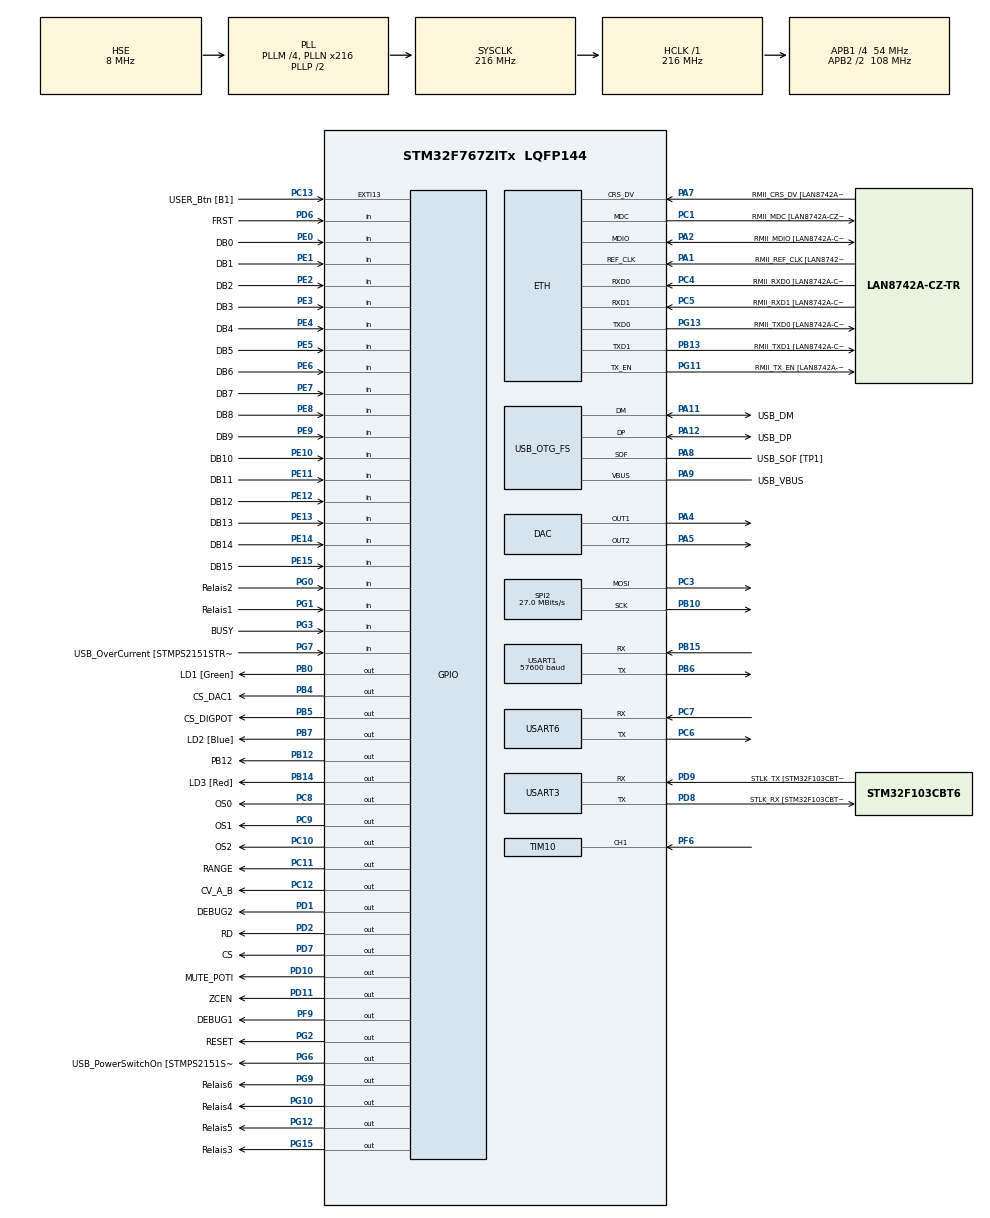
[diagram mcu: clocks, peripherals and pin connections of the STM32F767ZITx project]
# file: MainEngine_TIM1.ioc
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Dma.Request0=USART1_RX
Dma.Request1=USART6_RX
Dma.Request2=USART6_TX
Dma.USART1_RX.0.Direction=DMA_PERIPH_TO_MEMORY
Dma.USART1_RX.0.FIFOMode=DMA_FIFOMODE_DISABLE
Dma.USART1_RX.0.Instance=DMA2_Stream2
Dma.USART1_RX.0.MemDataAlignment=DMA_MDATAALIGN_BYTE
Dma.USART1_RX.0.MemInc=DMA_MINC_ENABLE
Dma.USART1_RX.0.Mode=DMA_CIRCULAR
Dma.USART1_RX.0.PeriphDataAlignment=DMA_PDATAALIGN_BYTE
Dma.USART1_RX.0.PeriphInc=DMA_PINC_DISABLE
Dma.USART1_RX.0.Priority=DMA_PRIORITY_LOW
Dma.USART6_RX.1.Direction=DMA_PERIPH_TO_MEMORY
Dma.USART6_RX.1.FIFOMode=DMA_FIFOMODE_DISABLE
Dma.USART6_RX.1.Instance=DMA2_Stream1
Dma.USART6_RX.1.MemDataAlignment=DMA_MDATAALIGN_BYTE
Dma.USART6_RX.1.MemInc=DMA_MINC_ENABLE
Dma.USART6_RX.1.Mode=DMA_CIRCULAR
Dma.USART6_RX.1.PeriphDataAlignment=DMA_PDATAALIGN_BYTE
Dma.USART6_RX.1.PeriphInc=DMA_PINC_DISABLE
Dma.USART6_RX.1.Priority=DMA_PRIORITY_LOW
Dma.USART6_TX.2.Direction=DMA_MEMORY_TO_PERIPH
Dma.USART6_TX.2.FIFOMode=DMA_FIFOMODE_DISABLE
Dma.USART6_TX.2.Instance=DMA2_Stream6
Dma.USART6_TX.2.MemDataAlignment=DMA_MDATAALIGN_BYTE
Dma.USART6_TX.2.MemInc=DMA_MINC_ENABLE
Dma.USART6_TX.2.Mode=DMA_CIRCULAR
Dma.USART6_TX.2.PeriphDataAlignment=DMA_PDATAALIGN_BYTE
Dma.USART6_TX.2.PeriphInc=DMA_PINC_DISABLE
Dma.USART6_TX.2.Priority=DMA_PRIORITY_LOW
ETH.MediaInterface=ETH_MEDIA_INTERFACE_RMII
ETH.PHY_Name=LAN8742A_PHY_ADDRESS
ETH.PHY_Value=0
ETH.PhyAddress=0
FREERTOS.Tasks01=defaultTask,0,2048,StartDefaultTask,Default,NULL,Dynamic,NULL,NULL
LWIP.IP_ADDRESS=192.168.001.070
LWIP.LWIP_DHCP=0
LWIP.LWIP_DNS=0
LWIP.LWIP_HTTPD=1
LWIP.NETMASK_ADDRESS=255.255.255.000
LWIP.Version=v2.1.2_Cube
Mcu.Family=STM32F7
Mcu.Name=STM32F767ZITx
Mcu.Package=LQFP144
NVIC.DMA2_Stream1_IRQn=true\:1\:0\:true\:false\:true\:true\:false\:true
NVIC.DMA2_Stream2_IRQn=true\:1\:0\:true\:false\:true\:true\:false\:true
NVIC.DMA2_Stream6_IRQn=true\:1\:0\:true\:false\:true\:true\:false\:true
NVIC.ETH_IRQn=true\:5\:0\:true\:false\:true\:true\:false\:true
NVIC.PriorityGroup=NVIC_PRIORITYGROUP_4
NVIC.TIM1_UP_TIM10_IRQn=true\:0\:0\:false\:false\:true\:false\:true\:true
NVIC.TIM3_IRQn=true\:3\:0\:true\:false\:true\:true\:true\:true
NVIC.TIM5_IRQn=true\:1\:0\:true\:false\:true\:true\:true\:true
NVIC.TIM6_DAC_IRQn=true\:1\:0\:true\:false\:true\:true\:true\:true
NVIC.TIM7_IRQn=true\:1\:0\:true\:false\:true\:true\:true\:true
NVIC.TimeBase=TIM1_UP_TIM10_IRQn
NVIC.TimeBaseIP=TIM1
NVIC.USART1_IRQn=true\:1\:0\:true\:false\:true\:true\:true\:true
PA1.GPIO_Label=RMII_REF_CLK [LAN8742A-CZ-TR_REFCLK0]
PA1.Mode=RMII
PA1.Signal=ETH_REF_CLK
PA10.GPIO_Label=USB_ID
PA10.Signal=USB_OTG_FS_ID
PA11.GPIO_Label=USB_DM
PA11.Mode=Device_Only
PA11.Signal=USB_OTG_FS_DM
PA12.GPIO_Label=USB_DP
PA12.Mode=Device_Only
PA12.Signal=USB_OTG_FS_DP
PA13.GPIO_Label=TMS
PA13.Mode=Serial_Wire
PA13.Signal=SYS_JTMS-SWDIO
PA14.GPIO_Label=TCK
PA14.Mode=Serial_Wire
PA14.Signal=SYS_JTCK-SWCLK
PA2.GPIO_Label=RMII_MDIO [LAN8742A-CZ-TR_MDIO]
PA2.Mode=RMII
PA2.Signal=ETH_MDIO
PA4.Signal=COMP_DAC1_group
PA5.Signal=COMP_DAC2_group
PA7.GPIO_Label=RMII_CRS_DV [LAN8742A-CZ-TR_CRS_DV]
PA7.Mode=RMII
PA7.Signal=ETH_CRS_DV
PA8.GPIO_Label=USB_SOF [TP1]
PA8.Mode=Activate_SOF_FS
PA8.Signal=USB_OTG_FS_SOF
PA9.GPIO_Label=USB_VBUS
PA9.Mode=Activate_VBUS
PA9.Signal=USB_OTG_FS_VBUS
PB0.GPIO_Label=LD1 [Green]
PB0.Signal=GPIO_Output
PB10.Mode=TX_Only_Simplex_Unidirect_Master
PB10.Signal=SPI2_SCK
PB12.GPIO_Label=PB12
PB12.Signal=GPIO_Output
PB13.GPIO_Label=RMII_TXD1 [LAN8742A-CZ-TR_TXD1]
PB13.Mode=RMII
PB13.Signal=ETH_TXD1
PB14.GPIO_Label=LD3 [Red]
PB14.Signal=GPIO_Output
PB15.Mode=Asynchronous
PB15.Signal=USART1_RX
PB3.GPIO_Label=SWO
PB3.Signal=SYS_JTDO-SWO
PB4.GPIO_Label=CS_DAC1
PB4.Signal=GPIO_Output
PB5.GPIO_Label=CS_DIGPOT
PB5.Signal=GPIO_Output
PB6.Mode=Asynchronous
PB6.Signal=USART1_TX
PB7.GPIO_Label=LD2 [Blue]
PB7.Signal=GPIO_Output
PC1.GPIO_Label=RMII_MDC [LAN8742A-CZ-TR_MDC]
PC1.Mode=RMII
PC1.Signal=ETH_MDC
PC10.GPIO_Label=OS2
PC10.Signal=GPIO_Output
PC11.GPIO_Label=RANGE
PC11.Signal=GPIO_Output
PC12.GPIO_Label=CV_A_B
PC12.Signal=GPIO_Output
PC13.GPIO_Label=USER_Btn [B1]
PC13.Signal=GPXTI13
PC14/OSC32_IN.Mode=LSE-External-Oscillator
PC14/OSC32_IN.Signal=RCC_OSC32_IN
PC15/OSC32_OUT.Mode=LSE-External-Oscillator
PC15/OSC32_OUT.Signal=RCC_OSC32_OUT
PC3.Mode=TX_Only_Simplex_Unidirect_Master
PC3.Signal=SPI2_MOSI
PC4.GPIO_Label=RMII_RXD0 [LAN8742A-CZ-TR_RXD0]
PC4.Mode=RMII
PC4.Signal=ETH_RXD0
PC5.GPIO_Label=RMII_RXD1 [LAN8742A-CZ-TR_RXD1]
PC5.Mode=RMII
PC5.Signal=ETH_RXD1
PC6.Mode=Asynchronous
PC6.Signal=USART6_TX
PC7.Mode=Asynchronous
PC7.Signal=USART6_RX
PC8.GPIO_Label=OS0
PC8.Signal=GPIO_Output
PC9.GPIO_Label=OS1
PC9.Signal=GPIO_Output
PD1.GPIO_Label=DEBUG2
PD1.Signal=GPIO_Output
PD10.GPIO_Label=MUTE_POTI
PD10.Signal=GPIO_Output
PD11.GPIO_Label=ZCEN
PD11.Signal=GPIO_Output
PD2.GPIO_Label=RD
PD2.Signal=GPIO_Output
PD6.GPIO_Label=FRST
PD6.Signal=GPIO_Input
PD7.GPIO_Label=CS
PD7.Signal=GPIO_Output
PD8.GPIO_Label=STLK_RX [STM32F103CBT6_PA3]
PD8.Mode=Asynchronous
PD8.Signal=USART3_TX
PD9.GPIO_Label=STLK_TX [STM32F103CBT6_PA2]
PD9.Mode=Asynchronous
PD9.Signal=USART3_RX
PE0.GPIO_Label=DB0
PE0.Signal=GPIO_Input
PE1.GPIO_Label=DB1
PE1.Signal=GPIO_Input
PE10.GPIO_Label=DB10
PE10.Signal=GPIO_Input
PE11.GPIO_Label=DB11
PE11.Signal=GPIO_Input
PE12.GPIO_Label=DB12
PE12.Signal=GPIO_Input
PE13.GPIO_Label=DB13
PE13.Signal=GPIO_Input
PE14.GPIO_Label=DB14
PE14.Signal=GPIO_Input
PE15.GPIO_Label=DB15
PE15.Signal=GPIO_Input
PE2.GPIO_Label=DB2
PE2.Signal=GPIO_Input
PE3.GPIO_Label=DB3
PE3.Signal=GPIO_Input
PE4.GPIO_Label=DB4
PE4.Signal=GPIO_Input
PE5.GPIO_Label=DB5
PE5.Signal=GPIO_Input
PE6.GPIO_Label=DB6
PE6.Signal=GPIO_Input
PE7.GPIO_Label=DB7
PE7.Signal=GPIO_Input
PE8.GPIO_Label=DB8
PE8.Signal=GPIO_Input
PE9.GPIO_Label=DB9
PE9.Signal=GPIO_Input
PF6.Signal=S_TIM10_CH1
PF9.GPIO_Label=DEBUG1
PF9.Signal=GPIO_Output
PG0.GPIO_Label=Relais2
PG0.Signal=GPIO_Input
PG1.GPIO_Label=Relais1
PG1.Signal=GPIO_Input
PG10.GPIO_Label=Relais4
PG10.Signal=GPIO_Output
PG11.GPIO_Label=RMII_TX_EN [LAN8742A-CZ-TR_TXEN]
PG11.Mode=RMII
PG11.Signal=ETH_TX_EN
PG12.GPIO_Label=Relais5
PG12.Signal=GPIO_Output
PG13.GPIO_Label=RMII_TXD0 [LAN8742A-CZ-TR_TXD0]
PG13.Mode=RMII
PG13.Signal=ETH_TXD0
PG15.GPIO_Label=Relais3
PG15.Signal=GPIO_Output
PG2.GPIO_Label=RESET
PG2.Signal=GPIO_Output
PG3.GPIO_Label=BUSY
PG3.Signal=GPIO_Input
PG6.GPIO_Label=USB_PowerSwitchOn [STMPS2151STR_EN]
PG6.Signal=GPIO_Output
PG7.GPIO_Label=USB_OverCurrent [STMPS2151STR_FAULT]
PG7.Signal=GPIO_Input
PG9.GPIO_Label=Relais6
PG9.Signal=GPIO_Output
PH0/OSC_IN.GPIO_Label=MCO [STM32F103CBT6_PA8]
PH0/OSC_IN.Mode=HSE-External-Clock-Source
PH0/OSC_IN.Signal=RCC_OSC_IN
PH1/OSC_OUT.Mode=HSE-External-Clock-Source
PH1/OSC_OUT.Signal=RCC_OSC_OUT
ProjectManager.HeapSize=0x200
ProjectManager.StackSize=0x400
ProjectManager.TargetToolchain=STM32CubeIDE
RCC.48MHZClocksFreq_Value=24000000
RCC.AHBFreq_Value=216000000
RCC.APB1CLKDivider=RCC_HCLK_DIV4
RCC.APB1Freq_Value=54000000
RCC.APB1TimFreq_Value=108000000
RCC.APB2CLKDivider=RCC_HCLK_DIV2
RCC.APB2Freq_Value=108000000
RCC.APB2TimFreq_Value=216000000
RCC.CortexFreq_Value=216000000
RCC.HCLKFreq_Value=216000000
RCC.HSE_VALUE=8000000
RCC.HSI_VALUE=16000000
RCC.PLLM=4
RCC.PLLMUL=RCC_PLL_MUL9
RCC.PLLN=216
RCC.PLLQ=9
RCC.PRESCALERUSB=RCC_USBCLKSOURCE_PLL_DIV1_5
RCC.SYSCLKFreq_VALUE=216000000
RCC.SYSCLKSource=RCC_SYSCLKSOURCE_PLLCLK
RCC.SYSCLKSourceVirtual=RCC_SYSCLKSOURCE_PLLCLK
RCC.USBFreq_Value=48000000
RCC.VCOOutputFreq_Value=432000000
SH.COMP_DAC1_group.0=DAC_OUT1,DAC_OUT1
SH.COMP_DAC2_group.0=DAC_OUT2,DAC_OUT2
SH.S_TIM10_CH1.0=TIM10_CH1,Input_Capture1_from_TI1
SPI2.CalculateBaudRate=27.0 MBits/s
SPI2.Direction=SPI_DIRECTION_2LINES
SPI2.Mode=SPI_MODE_MASTER
SPI2.VirtualType=VM_MASTER
TIM10.Channel=TIM_CHANNEL_1
TIM10.ICPolarity_CH1=TIM_INPUTCHANNELPOLARITY_FALLING
TIM10.Period=0
TIM10.Prescaler=107
TIM3.Period=1000
TIM3.Prescaler=216
TIM5.Period=1000
TIM5.Prescaler=216
TIM5.TIM_MasterOutputTrigger=TIM_TRGO_UPDATE
TIM6.Prescaler=107
TIM7.Prescaler=107
USART1.BaudRate=57600
USART1.VirtualMode-Asynchronous=VM_ASYNC
USART3.VirtualMode-Asynchronous=VM_ASYNC
USART6.VirtualMode-Asynchronous=VM_ASYNC
USB_OTG_FS.VirtualMode=Device_Only
VP_FREERTOS_VS_CMSIS_V1.Mode=CMSIS_V1
VP_LWIP_VS_Enabled.Mode=Enabled
VP_SYS_VS_tim1.Mode=TIM1
VP_TIM10_VS_ClockSourceINT.Mode=Enable_Timer
VP_TIM3_VS_ClockSourceINT.Mode=Internal
VP_TIM5_VS_ClockSourceINT.Mode=Internal
VP_TIM6_VS_ClockSourceINT.Mode=Enable_Timer
VP_TIM7_VS_ClockSourceINT.Mode=Enable_Timer
board=NUCLEO-F767ZI

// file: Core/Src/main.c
/* USER CODE BEGIN Header */
/**
  ******************************************************************************
  * @file           : main.c
  * @brief          : Main program body
  ******************************************************************************
  * @attention
  *
  * <h2><center>&copy; Copyright (c) 2020 STMicroelectronics.
  * All rights reserved.</center></h2>
  *
  * This software component is licensed by ST under BSD 3-Clause license,
  * the "License"; You may not use this file except in compliance with the
  * License. You may obtain a copy of the License at:
  *                        opensource.org/licenses/BSD-3-Clause
  *
  ******************************************************************************
  */
/* USER CODE END Header */
#include "main.h"
#include "cmsis_os.h"
#include "lwip.h"

/* USER CODE BEGIN Includes */
#include "lwip/tcp.h"
#include "header.h"
#include <string.h>
#include "UART-Bridge.h"
#include "dspTask.h"
/* USER CODE END Includes */

DAC_HandleTypeDef hdac;

SPI_HandleTypeDef hspi2;

TIM_HandleTypeDef htim3;
TIM_HandleTypeDef htim5;
TIM_HandleTypeDef htim6;
TIM_HandleTypeDef htim7;
TIM_HandleTypeDef htim10;

UART_HandleTypeDef huart1;
UART_HandleTypeDef huart3;
UART_HandleTypeDef huart6;
DMA_HandleTypeDef hdma_usart1_rx;
DMA_HandleTypeDef hdma_usart6_rx;
DMA_HandleTypeDef hdma_usart6_tx;

PCD_HandleTypeDef hpcd_USB_OTG_FS;

osThreadId defaultTaskHandle;
/* USER CODE BEGIN PV */
osThreadId dspTaskHandle;
/* USER CODE END PV */

void SystemClock_Config(void);
static void MX_GPIO_Init(void);
static void MX_DMA_Init(void);
static void MX_USART3_UART_Init(void);
static void MX_USB_OTG_FS_PCD_Init(void);
static void MX_TIM3_Init(void);
static void MX_USART1_UART_Init(void);
static void MX_SPI2_Init(void);
static void MX_USART6_UART_Init(void);
static void MX_DAC_Init(void);
static void MX_TIM5_Init(void);
static void MX_TIM6_Init(void);
static void MX_TIM7_Init(void);
static void MX_TIM10_Init(void);
void StartDefaultTask(void const * argument);

/* USER CODE BEGIN PFP */
static void VectorBase_Config(void);
/* USER CODE END PFP */

int main(void)
{
  /* USER CODE BEGIN 1 */
	VectorBase_Config();

  /* USER CODE END 1 */

  /* MCU Configuration--------------------------------------------------------*/

  /* Reset of all peripherals, Initializes the Flash interface and the Systick. */
  HAL_Init();

  /* Configure the system clock */
  SystemClock_Config();

  /* Initialize all configured peripherals */
  MX_GPIO_Init();
  MX_DMA_Init();
  MX_USART3_UART_Init();
  MX_USB_OTG_FS_PCD_Init();
  MX_TIM3_Init();
  MX_USART1_UART_Init();
  MX_SPI2_Init();
  MX_USART6_UART_Init();
  MX_DAC_Init();
  MX_TIM5_Init();
  MX_TIM6_Init();
  MX_TIM7_Init();
  MX_TIM10_Init();
  /* USER CODE BEGIN 2 */
  SharedParamsWriteByIndex(0, 0);
  /* USER CODE END 2 */
  HAL_DAC_Start(&hdac, DAC_CHANNEL_1);
  HAL_DAC_Start(&hdac, DAC_CHANNEL_2);

  /* Create the thread(s) */
  /* definition and creation of defaultTask */
  osThreadDef(defaultTask, StartDefaultTask, osPriorityNormal, 0, 2048);
  defaultTaskHandle = osThreadCreate(osThread(defaultTask), NULL);

  /* USER CODE BEGIN RTOS_THREADS */

  osThreadDef(dspTask, dspTask, osPriorityNormal , 0, 2000);
  dspTaskHandle = osThreadCreate(osThread(dspTask), NULL);

  /* add threads, ... */
  /* USER CODE END RTOS_THREADS */

  /* Start scheduler */
  osKernelStart();

  /* We should never get here as control is now taken by the scheduler */
  /* Infinite loop */
  /* USER CODE BEGIN WHILE */
  while (1)
  {

	  for(int i= 0; i <10 ; i++){
		  HAL_GPIO_TogglePin(GPIOB, LD1_Pin|LD3_Pin|LD2_Pin);
		  HAL_Delay(500);
	  }
    /* USER CODE END WHILE */

    /* USER CODE BEGIN 3 */
	  for(int i= 0; i <10 ; i++){
		  HAL_GPIO_TogglePin(GPIOB, LD1_Pin|LD3_Pin|LD2_Pin);
		  HAL_Delay(50);
	  }
      SharedParamsWriteByIndex(0, 1);
      /* connection request received so start the bootloader */
      BootActivate();
  }
  /* USER CODE END 3 */
}

void SystemClock_Config(void)
{
  RCC_OscInitTypeDef RCC_OscInitStruct = {0};
  RCC_ClkInitTypeDef RCC_ClkInitStruct = {0};
  RCC_PeriphCLKInitTypeDef PeriphClkInitStruct = {0};

  /** Configure LSE Drive Capability
  */
  HAL_PWR_EnableBkUpAccess();
  /** Configure the main internal regulator output voltage
  */
  __HAL_RCC_PWR_CLK_ENABLE();
  __HAL_PWR_VOLTAGESCALING_CONFIG(PWR_REGULATOR_VOLTAGE_SCALE1);
  /** Initializes the RCC Oscillators according to the specified parameters
  * in the RCC_OscInitTypeDef structure.
  */
  RCC_OscInitStruct.OscillatorType = RCC_OSCILLATORTYPE_HSE;
  RCC_OscInitStruct.HSEState = RCC_HSE_BYPASS;
  RCC_OscInitStruct.PLL.PLLState = RCC_PLL_ON;
  RCC_OscInitStruct.PLL.PLLSource = RCC_PLLSOURCE_HSE;
  RCC_OscInitStruct.PLL.PLLM = 4;
  RCC_OscInitStruct.PLL.PLLN = 216;
  RCC_OscInitStruct.PLL.PLLP = RCC_PLLP_DIV2;
  RCC_OscInitStruct.PLL.PLLQ = 9;
  if (HAL_RCC_OscConfig(&RCC_OscInitStruct) != HAL_OK)
  {
    Error_Handler();
  }
  /** Activate the Over-Drive mode
  */
  if (HAL_PWREx_EnableOverDrive() != HAL_OK)
  {
    Error_Handler();
  }
  /** Initializes the CPU, AHB and APB buses clocks
  */
  RCC_ClkInitStruct.ClockType = RCC_CLOCKTYPE_HCLK|RCC_CLOCKTYPE_SYSCLK
                              |RCC_CLOCKTYPE_PCLK1|RCC_CLOCKTYPE_PCLK2;
  RCC_ClkInitStruct.SYSCLKSource = RCC_SYSCLKSOURCE_PLLCLK;
  RCC_ClkInitStruct.AHBCLKDivider = RCC_SYSCLK_DIV1;
  RCC_ClkInitStruct.APB1CLKDivider = RCC_HCLK_DIV4;
  RCC_ClkInitStruct.APB2CLKDivider = RCC_HCLK_DIV2;

  if (HAL_RCC_ClockConfig(&RCC_ClkInitStruct, FLASH_LATENCY_7) != HAL_OK)
  {
    Error_Handler();
  }
  PeriphClkInitStruct.PeriphClockSelection = RCC_PERIPHCLK_USART1|RCC_PERIPHCLK_USART3
                              |RCC_PERIPHCLK_USART6|RCC_PERIPHCLK_CLK48;
  PeriphClkInitStruct.Usart1ClockSelection = RCC_USART1CLKSOURCE_PCLK2;
  PeriphClkInitStruct.Usart3ClockSelection = RCC_USART3CLKSOURCE_PCLK1;
  PeriphClkInitStruct.Usart6ClockSelection = RCC_USART6CLKSOURCE_PCLK2;
  PeriphClkInitStruct.Clk48ClockSelection = RCC_CLK48SOURCE_PLL;
  if (HAL_RCCEx_PeriphCLKConfig(&PeriphClkInitStruct) != HAL_OK)
  {
    Error_Handler();
  }
}

static void MX_DAC_Init(void)
{

  DAC_ChannelConfTypeDef sConfig = {0};

  /** DAC Initialization
  */
  hdac.Instance = DAC;
  if (HAL_DAC_Init(&hdac) != HAL_OK)
  {
    Error_Handler();
  }
  /** DAC channel OUT1 config
  */
  sConfig.DAC_Trigger = DAC_TRIGGER_NONE;
  sConfig.DAC_OutputBuffer = DAC_OUTPUTBUFFER_ENABLE;
  if (HAL_DAC_ConfigChannel(&hdac, &sConfig, DAC_CHANNEL_1) != HAL_OK)
  {
    Error_Handler();
  }
  /** DAC channel OUT2 config
  */
  if (HAL_DAC_ConfigChannel(&hdac, &sConfig, DAC_CHANNEL_2) != HAL_OK)
  {
    Error_Handler();
  }

}

static void MX_SPI2_Init(void)
{

  /* SPI2 parameter configuration*/
  hspi2.Instance = SPI2;
  hspi2.Init.Mode = SPI_MODE_MASTER;
  hspi2.Init.Direction = SPI_DIRECTION_2LINES;
  hspi2.Init.DataSize = SPI_DATASIZE_4BIT;
  hspi2.Init.CLKPolarity = SPI_POLARITY_LOW;
  hspi2.Init.CLKPhase = SPI_PHASE_1EDGE;
  hspi2.Init.NSS = SPI_NSS_SOFT;
  hspi2.Init.BaudRatePrescaler = SPI_BAUDRATEPRESCALER_2;
  hspi2.Init.FirstBit = SPI_FIRSTBIT_MSB;
  hspi2.Init.TIMode = SPI_TIMODE_DISABLE;
  hspi2.Init.CRCCalculation = SPI_CRCCALCULATION_DISABLE;
  hspi2.Init.CRCPolynomial = 7;
  hspi2.Init.CRCLength = SPI_CRC_LENGTH_DATASIZE;
  hspi2.Init.NSSPMode = SPI_NSS_PULSE_ENABLE;
  if (HAL_SPI_Init(&hspi2) != HAL_OK)
  {
    Error_Handler();
  }

}

static void MX_TIM3_Init(void)
{

  TIM_ClockConfigTypeDef sClockSourceConfig = {0};
  TIM_MasterConfigTypeDef sMasterConfig = {0};

  htim3.Instance = TIM3;
  htim3.Init.Prescaler = 216;
  htim3.Init.CounterMode = TIM_COUNTERMODE_UP;
  htim3.Init.Period = 1000;
  htim3.Init.ClockDivision = TIM_CLOCKDIVISION_DIV1;
  htim3.Init.AutoReloadPreload = TIM_AUTORELOAD_PRELOAD_DISABLE;
  if (HAL_TIM_Base_Init(&htim3) != HAL_OK)
  {
    Error_Handler();
  }
  sClockSourceConfig.ClockSource = TIM_CLOCKSOURCE_INTERNAL;
  if (HAL_TIM_ConfigClockSource(&htim3, &sClockSourceConfig) != HAL_OK)
  {
    Error_Handler();
  }
  sMasterConfig.MasterOutputTrigger = TIM_TRGO_RESET;
  sMasterConfig.MasterSlaveMode = TIM_MASTERSLAVEMODE_DISABLE;
  if (HAL_TIMEx_MasterConfigSynchronization(&htim3, &sMasterConfig) != HAL_OK)
  {
    Error_Handler();
  }

}

static void MX_TIM5_Init(void)
{

  TIM_ClockConfigTypeDef sClockSourceConfig = {0};
  TIM_MasterConfigTypeDef sMasterConfig = {0};

  htim5.Instance = TIM5;
  htim5.Init.Prescaler = 216;
  htim5.Init.CounterMode = TIM_COUNTERMODE_UP;
  htim5.Init.Period = 1000;
  htim5.Init.ClockDivision = TIM_CLOCKDIVISION_DIV1;
  htim5.Init.AutoReloadPreload = TIM_AUTORELOAD_PRELOAD_DISABLE;
  if (HAL_TIM_Base_Init(&htim5) != HAL_OK)
  {
    Error_Handler();
  }
  sClockSourceConfig.ClockSource = TIM_CLOCKSOURCE_INTERNAL;
  if (HAL_TIM_ConfigClockSource(&htim5, &sClockSourceConfig) != HAL_OK)
  {
    Error_Handler();
  }
  sMasterConfig.MasterOutputTrigger = TIM_TRGO_UPDATE;
  sMasterConfig.MasterSlaveMode = TIM_MASTERSLAVEMODE_DISABLE;
  if (HAL_TIMEx_MasterConfigSynchronization(&htim5, &sMasterConfig) != HAL_OK)
  {
    Error_Handler();
  }

}

static void MX_TIM6_Init(void)
{

  TIM_MasterConfigTypeDef sMasterConfig = {0};

  htim6.Instance = TIM6;
  htim6.Init.Prescaler = 107;
  htim6.Init.CounterMode = TIM_COUNTERMODE_UP;
  htim6.Init.Period = 65535;
  htim6.Init.AutoReloadPreload = TIM_AUTORELOAD_PRELOAD_DISABLE;
  if (HAL_TIM_Base_Init(&htim6) != HAL_OK)
  {
    Error_Handler();
  }
  sMasterConfig.MasterOutputTrigger = TIM_TRGO_RESET;
  sMasterConfig.MasterSlaveMode = TIM_MASTERSLAVEMODE_DISABLE;
  if (HAL_TIMEx_MasterConfigSynchronization(&htim6, &sMasterConfig) != HAL_OK)
  {
    Error_Handler();
  }

}

static void MX_TIM7_Init(void)
{

  TIM_MasterConfigTypeDef sMasterConfig = {0};

  htim7.Instance = TIM7;
  htim7.Init.Prescaler = 107;
  htim7.Init.CounterMode = TIM_COUNTERMODE_UP;
  htim7.Init.Period = 65535;
  htim7.Init.AutoReloadPreload = TIM_AUTORELOAD_PRELOAD_DISABLE;
  if (HAL_TIM_Base_Init(&htim7) != HAL_OK)
  {
    Error_Handler();
  }
  sMasterConfig.MasterOutputTrigger = TIM_TRGO_RESET;
  sMasterConfig.MasterSlaveMode = TIM_MASTERSLAVEMODE_DISABLE;
  if (HAL_TIMEx_MasterConfigSynchronization(&htim7, &sMasterConfig) != HAL_OK)
  {
    Error_Handler();
  }

}

static void MX_TIM10_Init(void)
{

  TIM_IC_InitTypeDef sConfigIC = {0};

  htim10.Instance = TIM10;
  htim10.Init.Prescaler = 107;
  htim10.Init.CounterMode = TIM_COUNTERMODE_UP;
  htim10.Init.Period = 0;
  htim10.Init.ClockDivision = TIM_CLOCKDIVISION_DIV1;
  htim10.Init.AutoReloadPreload = TIM_AUTORELOAD_PRELOAD_DISABLE;
  if (HAL_TIM_Base_Init(&htim10) != HAL_OK)
  {
    Error_Handler();
  }
  if (HAL_TIM_IC_Init(&htim10) != HAL_OK)
  {
    Error_Handler();
  }
  sConfigIC.ICPolarity = TIM_INPUTCHANNELPOLARITY_FALLING;
  sConfigIC.ICSelection = TIM_ICSELECTION_DIRECTTI;
  sConfigIC.ICPrescaler = TIM_ICPSC_DIV1;
  sConfigIC.ICFilter = 0;
  if (HAL_TIM_IC_ConfigChannel(&htim10, &sConfigIC, TIM_CHANNEL_1) != HAL_OK)
  {
    Error_Handler();
  }

}

static void MX_USART1_UART_Init(void)
{

  huart1.Instance = USART1;
  huart1.Init.BaudRate = 57600;
  huart1.Init.WordLength = UART_WORDLENGTH_8B;
  huart1.Init.StopBits = UART_STOPBITS_1;
  huart1.Init.Parity = UART_PARITY_NONE;
  huart1.Init.Mode = UART_MODE_TX_RX;
  huart1.Init.HwFlowCtl = UART_HWCONTROL_NONE;
  huart1.Init.OverSampling = UART_OVERSAMPLING_16;
  huart1.Init.OneBitSampling = UART_ONE_BIT_SAMPLE_DISABLE;
  huart1.AdvancedInit.AdvFeatureInit = UART_ADVFEATURE_NO_INIT;
  if (HAL_UART_Init(&huart1) != HAL_OK)
  {
    Error_Handler();
  }

}

static void MX_USART3_UART_Init(void)
{

  huart3.Instance = USART3;
  huart3.Init.BaudRate = 115200;
  huart3.Init.WordLength = UART_WORDLENGTH_8B;
  huart3.Init.StopBits = UART_STOPBITS_1;
  huart3.Init.Parity = UART_PARITY_NONE;
  huart3.Init.Mode = UART_MODE_TX_RX;
  huart3.Init.HwFlowCtl = UART_HWCONTROL_NONE;
  huart3.Init.OverSampling = UART_OVERSAMPLING_16;
  huart3.Init.OneBitSampling = UART_ONE_BIT_SAMPLE_DISABLE;
  huart3.AdvancedInit.AdvFeatureInit = UART_ADVFEATURE_NO_INIT;
  if (HAL_UART_Init(&huart3) != HAL_OK)
  {
    Error_Handler();
  }

}

static void MX_USART6_UART_Init(void)
{

  huart6.Instance = USART6;
  huart6.Init.BaudRate = 115200;
  huart6.Init.WordLength = UART_WORDLENGTH_8B;
  huart6.Init.StopBits = UART_STOPBITS_1;
  huart6.Init.Parity = UART_PARITY_NONE;
  huart6.Init.Mode = UART_MODE_TX_RX;
  huart6.Init.HwFlowCtl = UART_HWCONTROL_NONE;
  huart6.Init.OverSampling = UART_OVERSAMPLING_16;
  huart6.Init.OneBitSampling = UART_ONE_BIT_SAMPLE_DISABLE;
  huart6.AdvancedInit.AdvFeatureInit = UART_ADVFEATURE_NO_INIT;
  if (HAL_UART_Init(&huart6) != HAL_OK)
  {
    Error_Handler();
  }

}

static void MX_USB_OTG_FS_PCD_Init(void)
{

  hpcd_USB_OTG_FS.Instance = USB_OTG_FS;
  hpcd_USB_OTG_FS.Init.dev_endpoints = 6;
  hpcd_USB_OTG_FS.Init.speed = PCD_SPEED_FULL;
  hpcd_USB_OTG_FS.Init.dma_enable = DISABLE;
  hpcd_USB_OTG_FS.Init.phy_itface = PCD_PHY_EMBEDDED;
  hpcd_USB_OTG_FS.Init.Sof_enable = ENABLE;
  hpcd_USB_OTG_FS.Init.low_power_enable = DISABLE;
  hpcd_USB_OTG_FS.Init.lpm_enable = DISABLE;
  hpcd_USB_OTG_FS.Init.vbus_sensing_enable = ENABLE;
  hpcd_USB_OTG_FS.Init.use_dedicated_ep1 = DISABLE;
  if (HAL_PCD_Init(&hpcd_USB_OTG_FS) != HAL_OK)
  {
    Error_Handler();
  }

}

static void MX_DMA_Init(void)
{

  /* DMA controller clock enable */
  __HAL_RCC_DMA2_CLK_ENABLE();

  /* DMA interrupt init */
  /* DMA2_Stream1_IRQn interrupt configuration */
  HAL_NVIC_SetPriority(DMA2_Stream1_IRQn, 1, 0);
  HAL_NVIC_EnableIRQ(DMA2_Stream1_IRQn);
  /* DMA2_Stream2_IRQn interrupt configuration */
  HAL_NVIC_SetPriority(DMA2_Stream2_IRQn, 1, 0);
  HAL_NVIC_EnableIRQ(DMA2_Stream2_IRQn);
  /* DMA2_Stream6_IRQn interrupt configuration */
  HAL_NVIC_SetPriority(DMA2_Stream6_IRQn, 1, 0);
  HAL_NVIC_EnableIRQ(DMA2_Stream6_IRQn);

}

static void MX_GPIO_Init(void)
{
  GPIO_InitTypeDef GPIO_InitStruct = {0};

  /* GPIO Ports Clock Enable */
  __HAL_RCC_GPIOE_CLK_ENABLE();
  __HAL_RCC_GPIOC_CLK_ENABLE();
  __HAL_RCC_GPIOF_CLK_ENABLE();
  __HAL_RCC_GPIOH_CLK_ENABLE();
  __HAL_RCC_GPIOA_CLK_ENABLE();
  __HAL_RCC_GPIOB_CLK_ENABLE();
  __HAL_RCC_GPIOG_CLK_ENABLE();
  __HAL_RCC_GPIOD_CLK_ENABLE();

  /*Configure GPIO pin Output Level */
  HAL_GPIO_WritePin(DEBUG1_GPIO_Port, DEBUG1_Pin, GPIO_PIN_RESET);

  /*Configure GPIO pin Output Level */
  HAL_GPIO_WritePin(GPIOB, LD1_Pin|PB12_Pin|LD3_Pin|CS_DAC1_Pin
                          |CS_DIGPOT_Pin|LD2_Pin, GPIO_PIN_RESET);

  /*Configure GPIO pin Output Level */
  HAL_GPIO_WritePin(GPIOD, MUTE_POTI_Pin|ZCEN_Pin|DEBUG2_Pin|RD_Pin
                          |CS_Pin, GPIO_PIN_RESET);

  /*Configure GPIO pin Output Level */
  HAL_GPIO_WritePin(GPIOG, RESET_Pin|USB_PowerSwitchOn_Pin|Relais6_Pin|Relais4_Pin
                          |Relais5_Pin|Relais3_Pin, GPIO_PIN_RESET);

  /*Configure GPIO pin Output Level */
  HAL_GPIO_WritePin(GPIOC, OS0_Pin|OS1_Pin|OS2_Pin|RANGE_Pin
                          |CV_A_B_Pin, GPIO_PIN_RESET);

  /*Configure GPIO pins : DB2_Pin DB3_Pin DB4_Pin DB5_Pin
                           DB6_Pin DB7_Pin DB8_Pin DB9_Pin
                           DB10_Pin DB11_Pin DB12_Pin DB13_Pin
                           DB14_Pin DB15_Pin DB0_Pin DB1_Pin */
  GPIO_InitStruct.Pin = DB2_Pin|DB3_Pin|DB4_Pin|DB5_Pin
                          |DB6_Pin|DB7_Pin|DB8_Pin|DB9_Pin
                          |DB10_Pin|DB11_Pin|DB12_Pin|DB13_Pin
                          |DB14_Pin|DB15_Pin|DB0_Pin|DB1_Pin;
  GPIO_InitStruct.Mode = GPIO_MODE_INPUT;
  GPIO_InitStruct.Pull = GPIO_NOPULL;
  HAL_GPIO_Init(GPIOE, &GPIO_InitStruct);

  /*Configure GPIO pin : USER_Btn_Pin */
  GPIO_InitStruct.Pin = USER_Btn_Pin;
  GPIO_InitStruct.Mode = GPIO_MODE_IT_RISING;
  GPIO_InitStruct.Pull = GPIO_NOPULL;
  HAL_GPIO_Init(USER_Btn_GPIO_Port, &GPIO_InitStruct);

  /*Configure GPIO pin : DEBUG1_Pin */
  GPIO_InitStruct.Pin = DEBUG1_Pin;
  GPIO_InitStruct.Mode = GPIO_MODE_OUTPUT_PP;
  GPIO_InitStruct.Pull = GPIO_NOPULL;
  GPIO_InitStruct.Speed = GPIO_SPEED_FREQ_LOW;
  HAL_GPIO_Init(DEBUG1_GPIO_Port, &GPIO_InitStruct);

  /*Configure GPIO pins : LD1_Pin PB12_Pin LD3_Pin CS_DAC1_Pin
                           CS_DIGPOT_Pin LD2_Pin */
  GPIO_InitStruct.Pin = LD1_Pin|PB12_Pin|LD3_Pin|CS_DAC1_Pin
                          |CS_DIGPOT_Pin|LD2_Pin;
  GPIO_InitStruct.Mode = GPIO_MODE_OUTPUT_PP;
  GPIO_InitStruct.Pull = GPIO_NOPULL;
  GPIO_InitStruct.Speed = GPIO_SPEED_FREQ_LOW;
  HAL_GPIO_Init(GPIOB, &GPIO_InitStruct);

  /*Configure GPIO pins : Relais2_Pin Relais1_Pin BUSY_Pin USB_OverCurrent_Pin */
  GPIO_InitStruct.Pin = Relais2_Pin|Relais1_Pin|BUSY_Pin|USB_OverCurrent_Pin;
  GPIO_InitStruct.Mode = GPIO_MODE_INPUT;
  GPIO_InitStruct.Pull = GPIO_NOPULL;
  HAL_GPIO_Init(GPIOG, &GPIO_InitStruct);

  /*Configure GPIO pins : MUTE_POTI_Pin ZCEN_Pin DEBUG2_Pin RD_Pin
                           CS_Pin */
  GPIO_InitStruct.Pin = MUTE_POTI_Pin|ZCEN_Pin|DEBUG2_Pin|RD_Pin
                          |CS_Pin;
  GPIO_InitStruct.Mode = GPIO_MODE_OUTPUT_PP;
  GPIO_InitStruct.Pull = GPIO_NOPULL;
  GPIO_InitStruct.Speed = GPIO_SPEED_FREQ_LOW;
  HAL_GPIO_Init(GPIOD, &GPIO_InitStruct);

  /*Configure GPIO pins : RESET_Pin USB_PowerSwitchOn_Pin Relais6_Pin Relais4_Pin
                           Relais5_Pin Relais3_Pin */
  GPIO_InitStruct.Pin = RESET_Pin|USB_PowerSwitchOn_Pin|Relais6_Pin|Relais4_Pin
                          |Relais5_Pin|Relais3_Pin;
  GPIO_InitStruct.Mode = GPIO_MODE_OUTPUT_PP;
  GPIO_InitStruct.Pull = GPIO_NOPULL;
  GPIO_InitStruct.Speed = GPIO_SPEED_FREQ_LOW;
  HAL_GPIO_Init(GPIOG, &GPIO_InitStruct);

  /*Configure GPIO pins : OS0_Pin OS1_Pin OS2_Pin RANGE_Pin
                           CV_A_B_Pin */
  GPIO_InitStruct.Pin = OS0_Pin|OS1_Pin|OS2_Pin|RANGE_Pin
                          |CV_A_B_Pin;
  GPIO_InitStruct.Mode = GPIO_MODE_OUTPUT_PP;
  GPIO_InitStruct.Pull = GPIO_NOPULL;
  GPIO_InitStruct.Speed = GPIO_SPEED_FREQ_LOW;
  HAL_GPIO_Init(GPIOC, &GPIO_InitStruct);

  /*Configure GPIO pin : FRST_Pin */
  GPIO_InitStruct.Pin = FRST_Pin;
  GPIO_InitStruct.Mode = GPIO_MODE_INPUT;
  GPIO_InitStruct.Pull = GPIO_NOPULL;
  HAL_GPIO_Init(FRST_GPIO_Port, &GPIO_InitStruct);

}

/* USER CODE BEGIN 4 */
static void VectorBase_Config(void)
{
  /* The constant array with vectors of the vector table is declared externally in the
   * c-startup code.
   */
  extern const unsigned long g_pfnVectors[];

  /* Remap the vector table to where the vector table is located for this program. */
  SCB->VTOR = (unsigned long)&g_pfnVectors[0];
}

/* USER CODE END 4 */

/* USER CODE BEGIN Header_StartDefaultTask */
/**
  * @brief  Function implementing the defaultTask thread.
  * @param  argument: Not used
  * @retval None
  */

//##################################################################################//
//###################Callbacks for Bootloader activation############################//
//##################################################################################//

//https://www.xilinx.com/video/soc/networking-with-lwip-focused-free-rtos.html
//When we recive something we come here to accept the connection wish or not

err_t err;

err_t
recv_callback(void *arg, struct tcp_pcb *tpcb, struct pbuf *p, err_t err){

	char recived[50];
	tcp_recved(tpcb, p->len);
	memcpy(recived, p -> payload, p -> len); //put the incoming udp data to UDP_RECIVE
	pbuf_free(p);
}

err_t
accept_callback(void *arg, struct tcp_pcb *newpcb, err_t err){
	tcp_arg(newpcb,NULL);
	tcp_recv(newpcb, recv_callback);

	//Fire the Bootloader
	SharedParamsWriteByIndex(0, 1);
	BootActivate();
}

//##################################################################################//

/* USER CODE END Header_StartDefaultTask */
void StartDefaultTask(void const * argument)
{
  /* init code for LWIP */
  MX_LWIP_Init();
  /* USER CODE BEGIN 5 */
  httpd_init();

  //HAL_TIM_Base_Start_IT(&htim3);

  UartBridge_init();

  //########create pcb for firmware  upgrade on port 1000#########//
  static struct tcp_pcb *pcb;
  err_t err;
  pcb = tcp_new();
  err = tcp_bind(pcb, IP_ADDR_ANY, 1000);
  tcp_arg(pcb,NULL);
  pcb = tcp_listen(pcb);
  tcp_accept(pcb, accept_callback);
  //###############################################################//

  /* Infinite loop */
  for(;;)
  {
	  for(int i= 0; i <30; i++){
		  HAL_GPIO_TogglePin(GPIOB, LD1_Pin);
		  HAL_Delay(250);
	  }
    /* USER CODE END WHILE */

    /* USER CODE BEGIN 3 */
	  for(int i= 0; i <10 ; i++){
		  HAL_GPIO_TogglePin(GPIOB, LD1_Pin);
		  HAL_Delay(50);
	  }

  }

  /* USER CODE END 5 */
}

void HAL_TIM_PeriodElapsedCallback(TIM_HandleTypeDef *htim)
{
  if (htim->Instance == TIM1) {
    HAL_IncTick();
  }
}

void Error_Handler(void)
{
}

/************************ (C) COPYRIGHT STMicroelectronics *****END OF FILE****/
